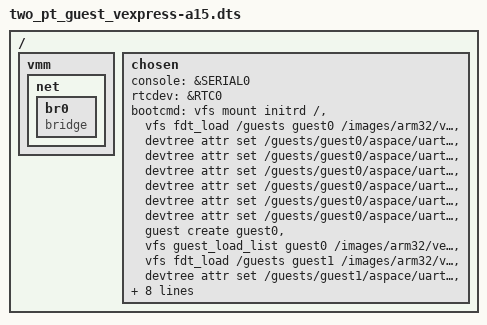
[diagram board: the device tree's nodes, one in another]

/dts-v1/;

#include "../foundation-v8-gicv3.dtsi"

/ {
	vmm {
		net {
			br0 {
				device_type = "netswitch";
				compatible = "bridge";
			};
		};
	};

	chosen {
		console = &SERIAL0;
		rtcdev = &RTC0;
		bootcmd = /* Mount initrd device */
			  "vfs mount initrd /",

			  /* Load guest0 device tree from file */
			  "vfs fdt_load /guests guest0 /images/arm32/vexpress-a15x2.dtb mem0,physical_size,physsize,0x06000000 net0,switch,string,br0 net1,switch,string,br0",

			  /* Map guest0/uart0 to host/uart1 */
			  "devtree attr set /guests/guest0/aspace/uart0 manifest_type string real",
			  "devtree attr set /guests/guest0/aspace/uart0 host_physical_addr physaddr 0x1c0a0000",
			  "devtree attr set /guests/guest0/aspace/uart0 device_type string pt",
			  "devtree attr set /guests/guest0/aspace/uart0 compatible string platform",
			  "devtree attr set /guests/guest0/aspace/uart0 host-interrupts uint32 38 4 0xffffffff",
			  "devtree attr set /guests/guest0/aspace/uart0 interrupts uint32 37",

			  /* Create guest0 */
			  "guest create guest0",

			  /* Load guest0 images */
			  "vfs guest_load_list guest0 /images/arm32/vexpress-a15/nor_flash.list",

			  /* Load guest1 device tree from file */
			  "vfs fdt_load /guests guest1 /images/arm32/vexpress-a15x2.dtb mem0,physical_size,physsize,0x06000000 net0,switch,string,br0 net1,switch,string,br0",

			  /* Map guest1/uart0 to host/uart2 */
			  "devtree attr set /guests/guest1/aspace/uart0 manifest_type string real",
			  "devtree attr set /guests/guest1/aspace/uart0 host_physical_addr physaddr 0x1c0b0000",
			  "devtree attr set /guests/guest1/aspace/uart0 device_type string pt",
			  "devtree attr set /guests/guest1/aspace/uart0 compatible string platform",
			  "devtree attr set /guests/guest1/aspace/uart0 host-interrupts uint32 39 4 0xffffffff",
			  "devtree attr set /guests/guest1/aspace/uart0 interrupts uint32 37",

			  /* Create guest1 */
			  "guest create guest1",

			  /* Load guest1 images */
			  "vfs guest_load_list guest1 /images/arm32/vexpress-a15/nor_flash.list",

			  /* Print banner */
			  "vfs cat /system/banner.txt";
	};
};
